# STM32U5A9 register map
File version: 1.0
CPU: CM33 r0p1, little endian, MPU, FPU, 4 interrupt priority bits
Registers are 32-bit, read-write, reset 0x0 unless marked. A register's access mark holds for its fields unless they carry their own. Offsets are from the block's base; [hi:lo] are bit positions; {n}, {i} and the like mark numbered series.

## SDMMC1 — Secure digital input/output MultiMediaCard interface
Base 0x420C8000
Same registers: SDMMC2 0x420C8C00, SEC_SDMMC1 0x520C8000, SEC_SDMMC2 0x520C8C00
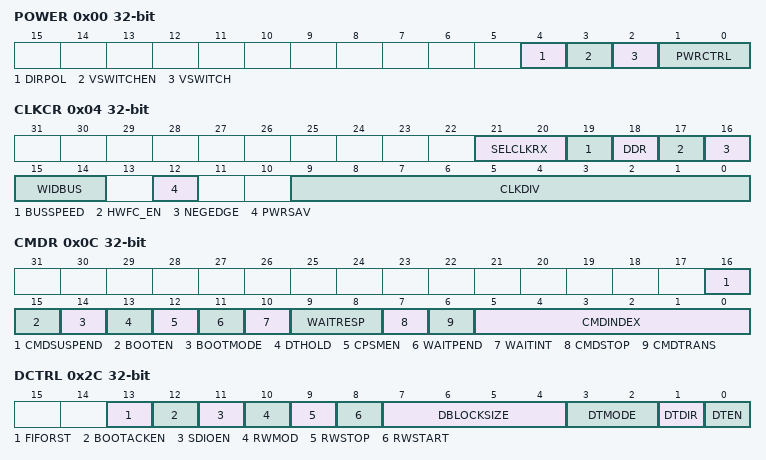
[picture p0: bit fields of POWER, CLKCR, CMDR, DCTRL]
0x00 POWER — power control register
  [4] DIRPOL — Data and command direction signals polarity selection
  [3] VSWITCHEN — Voltage switch procedure enable
  [2] VSWITCH — Voltage switch sequence start
  [1:0] PWRCTRL — SDMMC state control bits
0x04 CLKCR — clock control register
  [21:20] SELCLKRX — Receive clock selection
  [19] BUSSPEED — Bus speed mode selection between DS, HS, SDR12, SDR25 and SDR50,DDR50, SDR104
  [18] DDR — Data rate signaling selection
  [17] HWFC_EN — HW Flow Control enable
  [16] NEGEDGE — SDIO_CK dephasing selection bit
  [15:14] WIDBUS — Wide bus mode enable bit
  [12] PWRSAV — Power saving configuration bit
  [9:0] CLKDIV — Clock divide factor
0x08 ARGR — argument register
  [31:0] CMDARG — Command argument
0x0C CMDR — command register
  [16] CMDSUSPEND — The CPSM treats the command as a Suspend or Resume command and signals interrupt period start/end
  [15] BOOTEN — Enable boot mode procedure
  [14] BOOTMODE — Select the boot mode procedure to be used
  [13] DTHOLD — Hold new data block transmission and reception in the DPSM
  [12] CPSMEN — Command path state machine (CPSM) Enable bit
  [11] WAITPEND — CPSM Waits for ends of data transfer (CmdPend internal signal) from DPSM
  [10] WAITINT — CPSM waits for interrupt request
  [9:8] WAITRESP — Wait for response bits
  [7] CMDSTOP — The CPSM treats the command as a Stop Transmission command and signals Abort to the DPSM
  [6] CMDTRANS — The CPSM treats the command as a data transfer command, stops the interrupt period, and signals DataEnable to the DPSM
  [5:0] CMDINDEX — Command index
0x10 RESPCMDR ro — command response register
  [5:0] RESPCMD — Response command index
{0x10+4i} RESP{i} (i=1..4) ro — SDIO response {i} register
  [31:0] CARDSTATUS — Status of a card, which is part of the received response
0x24 DTIMER — data timer register
  [31:0] DATATIME — Data and R1b busy timeout period
0x28 DLENR — data length register
  [24:0] DATALENGTH — Data length value
0x2C DCTRL — data control register
  [13] FIFORST — FIFO reset, will flush any remaining data
  [12] BOOTACKEN — Enable the reception of the boot acknowledgment
  [11] SDIOEN — SD I/O enable functions
  [10] RWMOD — Read wait mode
  [9] RWSTOP — Read wait stop
  [8] RWSTART — Read wait start
  [7:4] DBLOCKSIZE — Data block size
  [3:2] DTMODE — Data transfer mode selection
  [1] DTDIR — Data transfer direction selection
  [0] DTEN
0x30 DCNTR ro — data counter register
  [24:0] DATACOUNT — Data count value
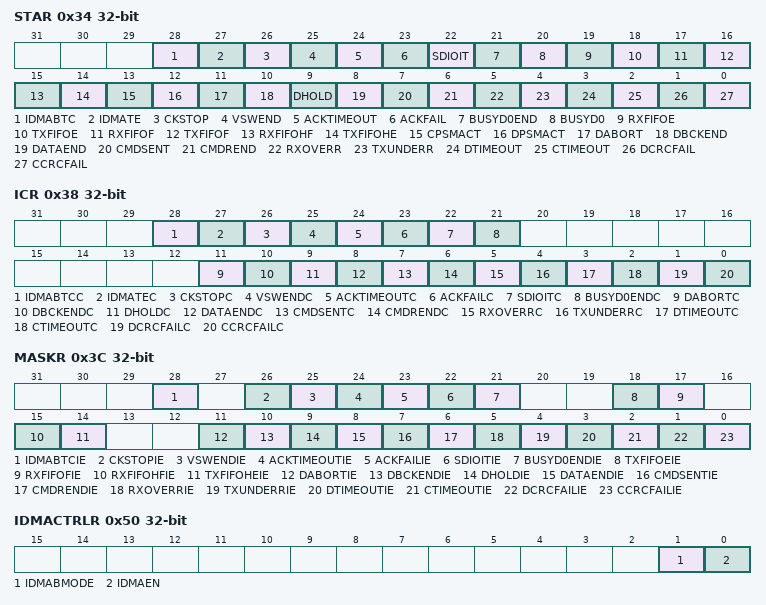
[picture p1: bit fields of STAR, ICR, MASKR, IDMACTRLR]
0x34 STAR ro — status register
  [28] IDMABTC — IDMA buffer transfer complete
  [27] IDMATE — IDMA transfer error
  [26] CKSTOP — SDMMC_CK stopped in Voltage switch procedure
  [25] VSWEND — Voltage switch critical timing section completion
  [24] ACKTIMEOUT — Boot acknowledgment timeout
  [23] ACKFAIL — Boot acknowledgment received (boot acknowledgment check fail)
  [22] SDIOIT — SDIO interrupt received
  [21] BUSYD0END — end of SDMMC_D0 Busy following a CMD response detected
  [20] BUSYD0 — Inverted value of SDMMC_D0 line (Busy), sampled at the end of a CMD response and a second time 2 SDMMC_CK cycles after the CMD response
  [19] RXFIFOE — Receive FIFO empty
  [18] TXFIFOE — Transmit FIFO empty
  [17] RXFIFOF — Receive FIFO full
  [16] TXFIFOF — Transmit FIFO full
  [15] RXFIFOHF — Receive FIFO half full
  [14] TXFIFOHE — Transmit FIFO half empty
  [13] CPSMACT — Command path state machine active, i.e. not in Idle state
  [12] DPSMACT — Data path state machine active, i.e. not in Idle state
  [11] DABORT — Data transfer aborted by CMD12
  [10] DBCKEND — Data block sent/received
  [9] DHOLD — Data transfer Hold
  [8] DATAEND — Data transfer ended correctly
  [7] CMDSENT — Command sent (no response required)
  [6] CMDREND — Command response received (CRC check passed, or no CRC)
  [5] RXOVERR — Received FIFO overrun error (masked by hardware when IDMA is enabled)
  [4] TXUNDERR — Transmit FIFO underrun error (masked by hardware when IDMA is enabled)
  [3] DTIMEOUT — Data timeout
  [2] CTIMEOUT — Command response timeout
  [1] DCRCFAIL — Data block sent/received (CRC check failed)
  [0] CCRCFAIL — Command response received (CRC check failed)
0x38 ICR — interrupt clear register
  [28] IDMABTCC — IDMA buffer transfer complete clear bit
  [27] IDMATEC — IDMA transfer error clear bit
  [26] CKSTOPC — CKSTOP flag clear bit
  [25] VSWENDC — VSWEND flag clear bit
  [24] ACKTIMEOUTC — ACKTIMEOUT flag clear bit
  [23] ACKFAILC — ACKFAIL flag clear bit
  [22] SDIOITC — SDIOIT flag clear bit
  [21] BUSYD0ENDC — BUSYD0END flag clear bit
  [11] DABORTC — DABORT flag clear bit
  [10] DBCKENDC — DBCKEND flag clear bit
  [9] DHOLDC — DHOLD flag clear bit
  [8] DATAENDC — DATAEND flag clear bit
  [7] CMDSENTC — CMDSENT flag clear bit
  [6] CMDRENDC — CMDREND flag clear bit
  [5] RXOVERRC — RXOVERR flag clear bit
  [4] TXUNDERRC — TXUNDERR flag clear bit
  [3] DTIMEOUTC — DTIMEOUT flag clear bit
  [2] CTIMEOUTC — CTIMEOUT flag clear bit
  [1] DCRCFAILC — DCRCFAIL flag clear bit
  [0] CCRCFAILC — CCRCFAIL flag clear bit
0x3C MASKR — mask register
  [28] IDMABTCIE — IDMA buffer transfer complete interrupt enable
  [26] CKSTOPIE — Voltage Switch clock stopped interrupt enable
  [25] VSWENDIE — Voltage switch critical timing section completion interrupt enable
  [24] ACKTIMEOUTIE — Acknowledgment timeout interrupt enable
  [23] ACKFAILIE — Acknowledgment Fail interrupt enable
  [22] SDIOITIE — SDIO mode interrupt received interrupt enable
  [21] BUSYD0ENDIE — BUSYD0END interrupt enable
  [18] TXFIFOEIE — Tx FIFO empty interrupt enable
  [17] RXFIFOFIE — Rx FIFO full interrupt enable
  [15] RXFIFOHFIE — Rx FIFO half full interrupt enable
  [14] TXFIFOHEIE — Tx FIFO half empty interrupt enable
  [11] DABORTIE — Data transfer aborted interrupt enable
  [10] DBCKENDIE — Data block end interrupt enable
  [9] DHOLDIE — Data hold interrupt enable
  [8] DATAENDIE — Data end interrupt enable
  [7] CMDSENTIE — Command sent interrupt enable
  [6] CMDRENDIE — Command response received interrupt enable
  [5] RXOVERRIE — Rx FIFO overrun error interrupt enable
  [4] TXUNDERRIE — Tx FIFO underrun error interrupt enable
  [3] DTIMEOUTIE — Data timeout interrupt enable
  [2] CTIMEOUTIE — Command timeout interrupt enable
  [1] DCRCFAILIE — Data CRC fail interrupt enable
  [0] CCRCFAILIE — Command CRC fail interrupt enable
0x40 ACKTIMER — acknowledgment timer register
  [24:0] ACKTIME — Boot acknowledgment timeout period
0x50 IDMACTRLR — DMA control register
  [1] IDMABMODE — Buffer mode selection. This bit can only be written by firmware when DPSM is inactive (DPSMACT = 0).
  [0] IDMAEN — IDMA enable This bit can only be written by firmware when DPSM is inactive (DPSMACT = 0).
0x54 IDMABSIZER — buffer size register
  [16:5] IDMABNDT — Number of bytes per buffer
0x58 IDMABASER — buffer base address register
  [31:0] IDMABASE — Buffer memory base address bits [31:2], shall be word aligned (bit [1:0] are always 0 and read only)
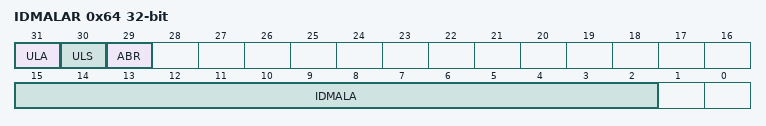
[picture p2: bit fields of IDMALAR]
0x64 IDMALAR — linked list address register
  [31] ULA — Update SDMMC_IDMALAR from linked list when in linked list mode (SDMMC_IDMACTRLR.IDMABMODE select linked list mode)
  [30] ULS — Update SDMMC_IDMABSIZE from the next linked list when in linked list mode (SDMMC_IDMACTRLR.IDMABMODE select linked list mode and ULA = 1)
  [29] ABR — Acknowledge linked list buffer ready
  [15:2] IDMALA — Acknowledge linked list buffer ready
0x68 IDMABAR — linked list memory base register
  [31:2] IDMABA — Word aligned Linked list memory base address
{0x80+4i} FIFOR{i} (i=0..15) — data FIFO register {i}
  [31:0] FIFODATA — Receive and transmit FIFO data
